VERSION ""

NS_ :

BS_:

BU_: Tester ECU_001

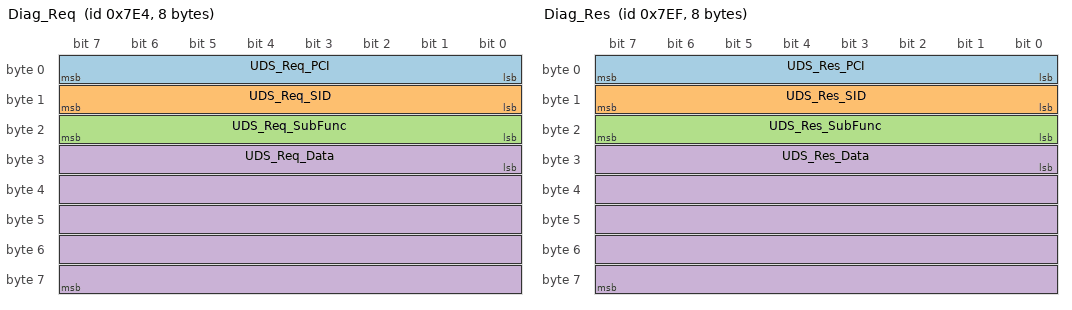
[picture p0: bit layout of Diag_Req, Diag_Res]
BO_ 2020 Diag_Req: 8 Tester
 SG_ UDS_Req_PCI      : 0|8@1+  (1,0) [0|255] ""  ECU_001
 SG_ UDS_Req_SID      : 8|8@1+  (1,0) [0|255] ""  ECU_001
 SG_ UDS_Req_SubFunc  : 16|8@1+ (1,0) [0|255] ""  ECU_001
 SG_ UDS_Req_Data     : 24|40@1+ (1,0) [0|0]  ""  ECU_001

BO_ 2031 Diag_Res: 8 ECU_001
 SG_ UDS_Res_PCI      : 0|8@1+  (1,0) [0|255] ""  Tester
 SG_ UDS_Res_SID      : 8|8@1+  (1,0) [0|255] ""  Tester
 SG_ UDS_Res_SubFunc  : 16|8@1+ (1,0) [0|255] ""  Tester
 SG_ UDS_Res_Data     : 24|40@1+ (1,0) [0|0]  ""  Tester

BO_TX_BU_ 2020 : Tester;
BO_TX_BU_ 2031 : ECU_001;

CM_ BU_ Tester   "UDS Tester / CANoe Diagnostic Tool – sends Requests, receives Responses";
CM_ BU_ ECU_001  "ECU under test – receives Requests, sends Responses";

CM_ BO_ 2020 "UDS Diagnostic Physical Request  | 0x7E4 | TX: Tester --> RX: ECU_001";
CM_ BO_ 2031 "UDS Diagnostic Physical Response | 0x7EF | TX: ECU_001 --> RX: Tester";

CM_ SG_ 2020 UDS_Req_PCI     "Byte 0 – PCI (Protocol Control Info): 0x0N = Single Frame (N=length)";
CM_ SG_ 2020 UDS_Req_SID     "Byte 1 – Service Identifier (e.g. 0x10=DiagSession, 0x22=ReadDID, 0x27=SecAccess)";
CM_ SG_ 2020 UDS_Req_SubFunc "Byte 2 – Sub-function or DID high byte / security level";
CM_ SG_ 2020 UDS_Req_Data    "Bytes 3-7 – Service-specific request parameters / DID low byte + data";

CM_ SG_ 2031 UDS_Res_PCI     "Byte 0 – PCI (Protocol Control Info): 0x0N = Single Frame (N=length)";
CM_ SG_ 2031 UDS_Res_SID     "Byte 1 – Response SID = Request SID + 0x40 (positive) or 0x7F (negative NRC)";
CM_ SG_ 2031 UDS_Res_SubFunc "Byte 2 – Sub-function echo or NRC (Negative Response Code)";
CM_ SG_ 2031 UDS_Res_Data    "Bytes 3-7 – Service-specific response data";

BA_DEF_  "BusType" STRING ;
BA_DEF_DEF_  "BusType" "CAN";
